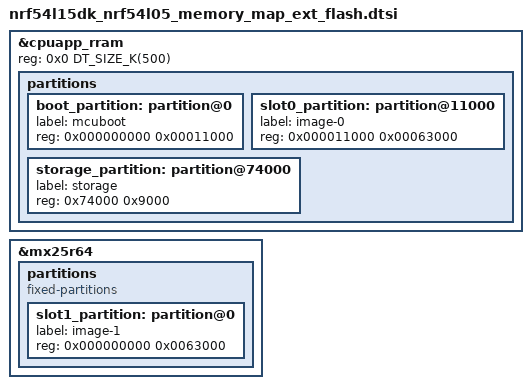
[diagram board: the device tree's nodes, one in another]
/delete-node/ &boot_partition;
/delete-node/ &slot0_partition;
/delete-node/ &slot1_partition;
/delete-node/ &storage_partition;

&cpuapp_rram {
	reg = <0x0 DT_SIZE_K(500)>;

	partitions {
		boot_partition: partition@0 {
			label = "mcuboot";
			reg = <0x000000000 0x00011000>;
		};

		slot0_partition: partition@11000 {
			label = "image-0";
			reg = <0x000011000 0x00063000>;
		};

		storage_partition: partition@74000 {
			label = "storage";
			reg = <0x74000 0x9000>;
		};
	};
};

&mx25r64 {
	partitions {
		compatible = "fixed-partitions";
		#address-cells = <1>;
		#size-cells = <1>;

		slot1_partition: partition@0 {
			label = "image-1";
			reg = <0x000000000 0x0063000>;
		};
	};
};
